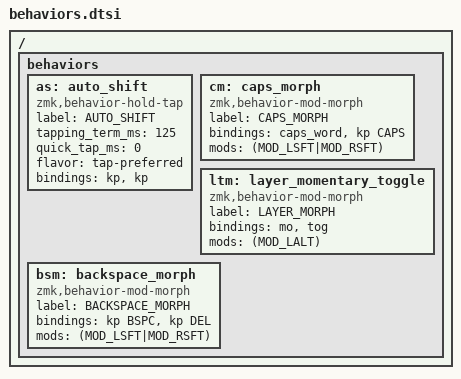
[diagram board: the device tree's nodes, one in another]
#define AS(keycode) &as LS(keycode) keycode
#define LTM(layer) &ltm layer layer

/ {
     behaviors {
          // Auto shift
          as: auto_shift {
               compatible = "zmk,behavior-hold-tap";
               label = "AUTO_SHIFT";
               #binding-cells = <2>;
               tapping_term_ms = <125>;
               quick_tap_ms = <0>;
               flavor = "tap-preferred";
               bindings = <&kp>, <&kp>;
          };
          cm: caps_morph {
               compatible = "zmk,behavior-mod-morph";
               label = "CAPS_MORPH";
               #binding-cells = <0>;
               bindings = <&caps_word>, <&kp CAPS>;
               mods = <(MOD_LSFT|MOD_RSFT)>;
          };
          ltm: layer_momentary_toggle {
               compatible = "zmk,behavior-mod-morph";
               label = "LAYER_MORPH";
               #binding-cells = <0>;
               bindings = <&mo>, <&tog>;
               mods = <(MOD_LALT)>;
          };
          bsm: backspace_morph {
               compatible = "zmk,behavior-mod-morph";
               label = "BACKSPACE_MORPH";
               #binding-cells = <0>;
               bindings = <&kp BSPC>, <&kp DEL>;
               mods = <(MOD_LSFT|MOD_RSFT)>;
          };
     };
};
